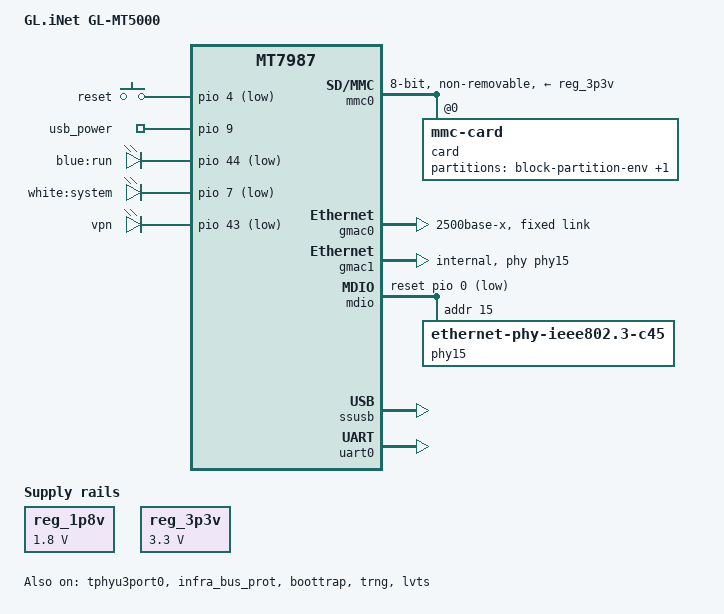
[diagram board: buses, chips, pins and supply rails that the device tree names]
/* SPDX-License-Identifier: (GPL-2.0 OR MIT) */

/dts-v1/;
#include "mt7987a.dtsi"
#include <dt-bindings/input/input.h>

/ {
	model = "GL.iNet GL-MT5000";
	compatible = "glinet,gl-mt5000",
				"mediatek,mt7987a", "mediatek,mt7987";

	aliases {
		label-mac-device = &gmac0;
		led-boot = &led_power;
		led-failsafe = &led_power;
		led-running = &led_power;
		led-upgrade = &led_power;
	};

	chosen {
		bootargs = "console=ttyS0,115200n1 loglevel=8  \
				earlycon=uart8250,mmio32,0x11000000 \
				root=PARTLABEL=rootfs rootwait \
			    rootfstype=squashfs,f2fs pci=pcie_bus_perf";
	};

	gpio-keys {
		compatible = "gpio-keys";

		reset {
			label = "reset";
			linux,code = <KEY_RESTART>;
			gpios = <&pio 4 GPIO_ACTIVE_LOW>;
			debounce-interval = <10>;
		};
	};

	gpio-export {
		compatible = "gpio-export";

		usb_power {
			gpio-export,name = "usb_power";
			gpio-export,output = <1>;
			gpios = <&pio 9 GPIO_ACTIVE_HIGH>;
		};
	};

	leds {
		compatible = "gpio-leds";

		led_power: led@0 {
			label = "blue:run";
			gpios = <&pio 44 GPIO_ACTIVE_LOW>;
			default-state = "on";
		};

		led@1 {
			label = "white:system";
			gpios = <&pio 7 GPIO_ACTIVE_LOW>;
		};

		led@2 {
			label = "vpn";
			gpios = <&pio 43 GPIO_ACTIVE_LOW>;
		};
	};

	reg_1p8v: regulator-1p8v {
		compatible = "regulator-fixed";
		regulator-name = "fixed-1.8V";
		regulator-min-microvolt = <1800000>;
		regulator-max-microvolt = <1800000>;
		regulator-boot-on;
		regulator-always-on;
	};

	reg_3p3v: regulator-3p3v {
		compatible = "regulator-fixed";
		regulator-name = "fixed-3.3V";
		regulator-min-microvolt = <3300000>;
		regulator-max-microvolt = <3300000>;
		regulator-boot-on;
		regulator-always-on;
	};	
};

&mmc0 {
	pinctrl-names = "default", "state_uhs";
	pinctrl-0 = <&mmc_pins_default>;
	pinctrl-1 = <&mmc_pins_uhs>;
	bus-width = <8>;
	max-frequency = <26000000>;
	cap-mmc-highspeed;
	vqmmc-supply = <&reg_3p3v>;
	vmmc-supply = <&reg_3p3v>;
	mmc-ddr-3_3v;
	non-removable;
	no-sd;
	no-sdio;
	status = "okay";

	card@0 {
		compatible = "mmc-card";
		reg = <0>;

		block {
			compatible = "block-device";
			partitions {
				block-partition-env {
					partname = "u-boot-env";

					nvmem-layout {
						compatible = "u-boot,env";
					};
				};

				block-partition-factory {
					partname = "factory";

					nvmem-layout {
						compatible = "fixed-layout";
						#address-cells = <1>;
						#size-cells = <1>;

						macaddr_base: macaddr@4000 {
							compatible = "mac-base";
							reg = <0x4000 0x6>;
							#nvmem-cell-cells = <1>;
						};
					};

				};
			};
		};
	};
};

&gmac0 {
	compatible = "mediatek,eth-mac";
	reg = <0>;
	mac-type = "gdm";
	phy-mode = "2500base-x";
	status = "okay";
	nvmem-cells = <&macaddr_base 0>;
	nvmem-cell-names = "mac-address";

	fixed-link {
		speed = <2500>;
		full-duplex;
		pause;
	};
};

&gmac1 {
	reg = <1>;
	mac-type = "xgdm";
	phy-mode = "internal";
	phy-handle = <&phy15>;
	status = "okay";
	nvmem-cells = <&macaddr_base 1>;
	nvmem-cell-names = "mac-address";
};

&mdio {
	#address-cells = <1>;
	#size-cells = <0>;
	reset-gpios = <&pio 0 GPIO_ACTIVE_LOW>;
	reset-delay-us = <10000>;

	phy15: phy@f {
		compatible = "ethernet-phy-ieee802.3-c45";
		reg = <15>;
		pinctrl-names = "i2p5gbe-led";
		pinctrl-0 = <&i2p5gbe_led0_pins>;
		phy-mode = "internal";
	};
};

&ssusb {
	status = "okay";
};

&tphyu3port0 {
	status = "okay";
};

&uart0 {
	pinctrl-names = "default";
	pinctrl-0 = <&uart0_pins>;
	status = "okay";
};

&infra_bus_prot {
	status = "okay";
};

&boottrap {
	status = "okay";
};

&trng {
	status = "okay";
};

&lvts {
	status = "okay";
};
